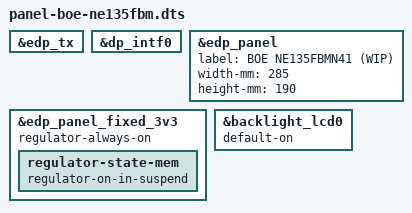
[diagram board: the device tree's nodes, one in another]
/dts-v1/;
/plugin/;

/ {
	fragment@0 {
		target = <&edp_tx>;
		__overlay__ {
			status = "okay";
		};
	};

	fragment@1 {
		target = <&dp_intf0>;
		__overlay__ {
			status = "okay";
		};
	};

	fragment@2 {
		target = <&edp_panel>;
		__overlay__ {
			status = "okay";

			label = "BOE NE135FBMN41 (WIP)";
			width-mm = <285>;
			height-mm = <190>;
		};
	};

	fragment@3 {
		target = <&edp_panel_fixed_3v3>;
		__overlay__ {
			regulator-always-on;

			regulator-state-mem {
				regulator-on-in-suspend;
			};
		};
	};

	fragment@4 {
		target = <&backlight_lcd0>;
		__overlay__ {
			default-on;
		};
	};
};
